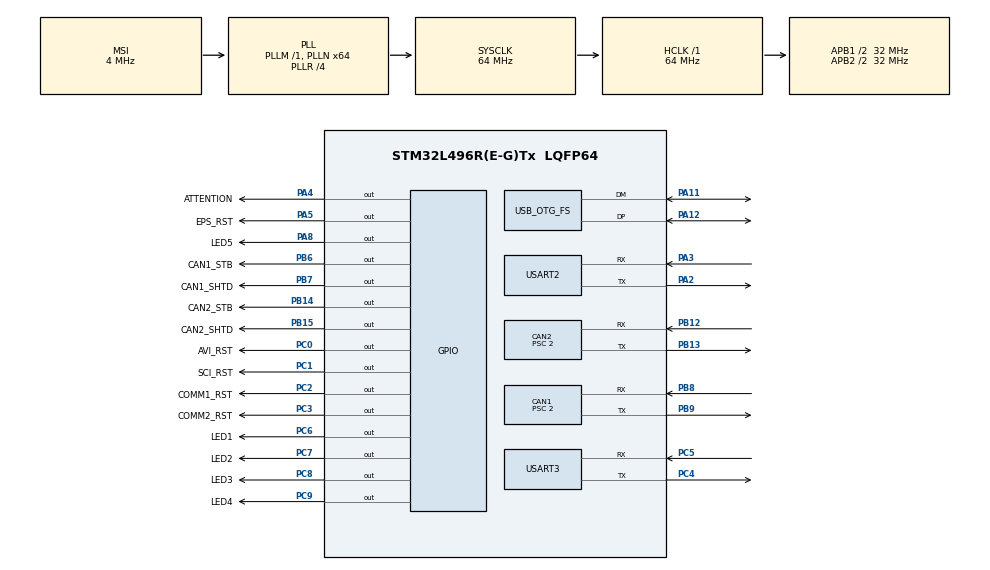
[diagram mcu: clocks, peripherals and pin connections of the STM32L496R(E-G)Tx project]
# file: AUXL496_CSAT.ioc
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CAN1.AWUM=ENABLE
CAN1.BS1=CAN_BS1_13TQ
CAN1.BS2=CAN_BS2_2TQ
CAN1.CalculateBaudRate=1000000
CAN1.CalculateTimeBit=1000
CAN1.CalculateTimeQuantum=62.5
CAN1.Prescaler=2
CAN1.TXFP=ENABLE
CAN2.AWUM=ENABLE
CAN2.BS1=CAN_BS1_13TQ
CAN2.BS2=CAN_BS2_2TQ
CAN2.CalculateBaudRate=1000000
CAN2.CalculateTimeBit=1000
CAN2.CalculateTimeQuantum=62.5
CAN2.Prescaler=2
CAN2.TXFP=ENABLE
Dma.Request0=USART2_RX
Dma.Request1=USART2_TX
Dma.Request2=USART3_RX
Dma.Request3=USART3_TX
Dma.USART2_RX.0.Direction=DMA_PERIPH_TO_MEMORY
Dma.USART2_RX.0.Instance=DMA1_Channel6
Dma.USART2_RX.0.MemDataAlignment=DMA_MDATAALIGN_BYTE
Dma.USART2_RX.0.MemInc=DMA_MINC_ENABLE
Dma.USART2_RX.0.Mode=DMA_NORMAL
Dma.USART2_RX.0.PeriphDataAlignment=DMA_PDATAALIGN_BYTE
Dma.USART2_RX.0.PeriphInc=DMA_PINC_DISABLE
Dma.USART2_RX.0.Priority=DMA_PRIORITY_LOW
Dma.USART2_TX.1.Direction=DMA_MEMORY_TO_PERIPH
Dma.USART2_TX.1.Instance=DMA1_Channel7
Dma.USART2_TX.1.MemDataAlignment=DMA_MDATAALIGN_BYTE
Dma.USART2_TX.1.MemInc=DMA_MINC_ENABLE
Dma.USART2_TX.1.Mode=DMA_NORMAL
Dma.USART2_TX.1.PeriphDataAlignment=DMA_PDATAALIGN_BYTE
Dma.USART2_TX.1.PeriphInc=DMA_PINC_DISABLE
Dma.USART2_TX.1.Priority=DMA_PRIORITY_LOW
Dma.USART3_RX.2.Direction=DMA_PERIPH_TO_MEMORY
Dma.USART3_RX.2.Instance=DMA1_Channel3
Dma.USART3_RX.2.MemDataAlignment=DMA_MDATAALIGN_BYTE
Dma.USART3_RX.2.MemInc=DMA_MINC_ENABLE
Dma.USART3_RX.2.Mode=DMA_NORMAL
Dma.USART3_RX.2.PeriphDataAlignment=DMA_PDATAALIGN_BYTE
Dma.USART3_RX.2.PeriphInc=DMA_PINC_DISABLE
Dma.USART3_RX.2.Priority=DMA_PRIORITY_LOW
Dma.USART3_TX.3.Direction=DMA_MEMORY_TO_PERIPH
Dma.USART3_TX.3.Instance=DMA1_Channel2
Dma.USART3_TX.3.MemDataAlignment=DMA_MDATAALIGN_BYTE
Dma.USART3_TX.3.MemInc=DMA_MINC_ENABLE
Dma.USART3_TX.3.Mode=DMA_NORMAL
Dma.USART3_TX.3.PeriphDataAlignment=DMA_PDATAALIGN_BYTE
Dma.USART3_TX.3.PeriphInc=DMA_PINC_DISABLE
Dma.USART3_TX.3.Priority=DMA_PRIORITY_LOW
Mcu.Family=STM32L4
Mcu.Name=STM32L496R(E-G)Tx
Mcu.Package=LQFP64
NVIC.CAN1_RX0_IRQn=true\:0\:0\:false\:false\:true\:true\:true\:true
NVIC.CAN1_RX1_IRQn=true\:0\:0\:false\:false\:true\:true\:true\:true
NVIC.CAN1_SCE_IRQn=true\:0\:0\:false\:false\:true\:true\:true\:true
NVIC.CAN2_RX0_IRQn=true\:0\:0\:false\:false\:true\:true\:true\:true
NVIC.CAN2_RX1_IRQn=true\:0\:0\:false\:false\:true\:true\:true\:true
NVIC.CAN2_SCE_IRQn=true\:0\:0\:false\:false\:true\:true\:true\:true
NVIC.DMA1_Channel2_IRQn=true\:0\:0\:false\:false\:true\:false\:true\:true
NVIC.DMA1_Channel3_IRQn=true\:0\:0\:false\:false\:true\:false\:true\:true
NVIC.DMA1_Channel6_IRQn=true\:0\:0\:false\:false\:true\:false\:true\:true
NVIC.DMA1_Channel7_IRQn=true\:0\:0\:false\:false\:true\:false\:true\:true
NVIC.OTG_FS_IRQn=true\:0\:0\:false\:false\:true\:false\:true\:true
NVIC.PriorityGroup=NVIC_PRIORITYGROUP_4
NVIC.USART2_IRQn=true\:0\:0\:false\:false\:true\:true\:true\:true
NVIC.USART3_IRQn=true\:0\:0\:false\:false\:true\:true\:true\:true
PA11.Mode=Device_Only
PA11.Signal=USB_OTG_FS_DM
PA12.Mode=Device_Only
PA12.Signal=USB_OTG_FS_DP
PA2.Mode=Asynchronous
PA2.Signal=USART2_TX
PA3.Mode=Asynchronous
PA3.Signal=USART2_RX
PA4.GPIO_Label=ATTENTION
PA4.PinState=GPIO_PIN_SET
PA4.Signal=GPIO_Output
PA5.GPIO_Label=EPS_RST
PA5.PinState=GPIO_PIN_SET
PA5.Signal=GPIO_Output
PA8.GPIO_Label=LED5
PA8.PinState=GPIO_PIN_RESET
PA8.Signal=GPIO_Output
PB12.Mode=CAN_Activate
PB12.Signal=CAN2_RX
PB13.Mode=CAN_Activate
PB13.Signal=CAN2_TX
PB14.GPIO_Label=CAN2_STB
PB14.Signal=GPIO_Output
PB15.GPIO_Label=CAN2_SHTD
PB15.Signal=GPIO_Output
PB6.GPIO_Label=CAN1_STB
PB6.Signal=GPIO_Output
PB7.GPIO_Label=CAN1_SHTD
PB7.Signal=GPIO_Output
PB8.Mode=CAN_Activate
PB8.Signal=CAN1_RX
PB9.Mode=CAN_Activate
PB9.Signal=CAN1_TX
PC0.GPIO_Label=AVI_RST
PC0.PinState=GPIO_PIN_SET
PC0.Signal=GPIO_Output
PC1.GPIO_Label=SCI_RST
PC1.PinState=GPIO_PIN_SET
PC1.Signal=GPIO_Output
PC2.GPIO_Label=COMM1_RST
PC2.PinState=GPIO_PIN_SET
PC2.Signal=GPIO_Output
PC3.GPIO_Label=COMM2_RST
PC3.PinState=GPIO_PIN_SET
PC3.Signal=GPIO_Output
PC4.Mode=Asynchronous
PC4.Signal=USART3_TX
PC5.Mode=Asynchronous
PC5.Signal=USART3_RX
PC6.GPIO_Label=LED1
PC6.Signal=GPIO_Output
PC7.GPIO_Label=LED2
PC7.Signal=GPIO_Output
PC8.GPIO_Label=LED3
PC8.Signal=GPIO_Output
PC9.GPIO_Label=LED4
PC9.Signal=GPIO_Output
ProjectManager.HeapSize=0x200
ProjectManager.StackSize=0x400
ProjectManager.TargetToolchain=STM32CubeIDE
RCC.ADCFreq_Value=48000000
RCC.AHBFreq_Value=64000000
RCC.APB1CLKDivider=RCC_HCLK_DIV2
RCC.APB1Freq_Value=32000000
RCC.APB1TimFreq_Value=64000000
RCC.APB2CLKDivider=RCC_HCLK_DIV2
RCC.APB2Freq_Value=32000000
RCC.APB2TimFreq_Value=64000000
RCC.CK48CLockSelection=RCC_USBCLKSOURCE_HSI48
RCC.CortexFreq_Value=64000000
RCC.FLatency=FLASH_LATENCY_3
RCC.HCLKFreq_Value=64000000
RCC.HSE_VALUE=8000000
RCC.HSI48_VALUE=48000000
RCC.HSI_VALUE=16000000
RCC.LSE_VALUE=32768
RCC.MSI_VALUE=4000000
RCC.PLLN=64
RCC.PLLR=RCC_PLLR_DIV4
RCC.PLLSAI1N=24
RCC.SYSCLKFreq_VALUE=64000000
RCC.SYSCLKSource=RCC_SYSCLKSOURCE_PLLCLK
RCC.USBFreq_Value=48000000
RCC.VCOOutputFreq_Value=256000000
USART2.SwapParam=ADVFEATURE_SWAP_ENABLE
USART2.VirtualMode-Asynchronous=VM_ASYNC
USART3.VirtualMode-Asynchronous=VM_ASYNC
USB_DEVICE.CLASS_NAME_FS=CDC
USB_DEVICE.VirtualMode=Cdc
USB_DEVICE.VirtualModeFS=Cdc_FS
USB_OTG_FS.VirtualMode=Device_Only
VP_RTC_VS_RTC_Activate.Mode=RTC_Enabled
VP_USB_DEVICE_VS_USB_DEVICE_CDC_FS.Mode=CDC_FS
board=custom

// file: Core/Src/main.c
/* USER CODE BEGIN Header */
/**
  ******************************************************************************
  * @file           : main.c
  * @brief          : Main program body
  ******************************************************************************
  * @attention
  *
  * Copyright (c) 2025 STMicroelectronics.
  * All rights reserved.
  *
  * This software is licensed under terms that can be found in the LICENSE file
  * in the root directory of this software component.
  * If no LICENSE file comes with this software, it is provided AS-IS.
  *
  ******************************************************************************
  */
/* USER CODE END Header */
#include "main.h"
#include "usb_device.h"

/* USER CODE BEGIN Includes */
#include "cppmain.h"
/* USER CODE END Includes */

CAN_HandleTypeDef hcan1;
CAN_HandleTypeDef hcan2;

RTC_HandleTypeDef hrtc;

UART_HandleTypeDef huart2;
UART_HandleTypeDef huart3;
DMA_HandleTypeDef hdma_usart2_rx;
DMA_HandleTypeDef hdma_usart2_tx;
DMA_HandleTypeDef hdma_usart3_rx;
DMA_HandleTypeDef hdma_usart3_tx;

void SystemClock_Config(void);
static void MX_GPIO_Init(void);
static void MX_DMA_Init(void);
static void MX_USART2_UART_Init(void);
static void MX_USART3_UART_Init(void);
static void MX_CAN1_Init(void);
static void MX_CAN2_Init(void);
static void MX_RTC_Init(void);

/* USER CODE BEGIN 0 */
extern int getentropy(void* buffer, size_t length) {
    (void)buffer;
    (void)length;
    return -1; // ENOSYS: Function not implemented
}
/* USER CODE END 0 */

int main(void)
{

  /* MCU Configuration--------------------------------------------------------*/

  /* Reset of all peripherals, Initializes the Flash interface and the Systick. */
  HAL_Init();

  /* Configure the system clock */
  SystemClock_Config();

  /* Initialize all configured peripherals */
  MX_GPIO_Init();
  MX_DMA_Init();
  MX_USART2_UART_Init();
  MX_USART3_UART_Init();
  MX_USB_DEVICE_Init();
  MX_CAN1_Init();
  MX_CAN2_Init();
  MX_RTC_Init();
  /* USER CODE BEGIN 2 */
  cppmain();

  /* USER CODE END 2 */

  /* Infinite loop */
  while (1)
  {

  }
}

void SystemClock_Config(void)
{
  RCC_OscInitTypeDef RCC_OscInitStruct = {0};
  RCC_ClkInitTypeDef RCC_ClkInitStruct = {0};

  /** Configure the main internal regulator output voltage
  */
  if (HAL_PWREx_ControlVoltageScaling(PWR_REGULATOR_VOLTAGE_SCALE1) != HAL_OK)
  {
    Error_Handler();
  }

  /** Initializes the RCC Oscillators according to the specified parameters
  * in the RCC_OscInitTypeDef structure.
  */
  RCC_OscInitStruct.OscillatorType = RCC_OSCILLATORTYPE_HSI48|RCC_OSCILLATORTYPE_LSI
                              |RCC_OSCILLATORTYPE_MSI;
  RCC_OscInitStruct.HSI48State = RCC_HSI48_ON;
  RCC_OscInitStruct.LSIState = RCC_LSI_ON;
  RCC_OscInitStruct.MSIState = RCC_MSI_ON;
  RCC_OscInitStruct.MSICalibrationValue = 0;
  RCC_OscInitStruct.MSIClockRange = RCC_MSIRANGE_6;
  RCC_OscInitStruct.PLL.PLLState = RCC_PLL_ON;
  RCC_OscInitStruct.PLL.PLLSource = RCC_PLLSOURCE_MSI;
  RCC_OscInitStruct.PLL.PLLM = 1;
  RCC_OscInitStruct.PLL.PLLN = 64;
  RCC_OscInitStruct.PLL.PLLP = RCC_PLLP_DIV2;
  RCC_OscInitStruct.PLL.PLLQ = RCC_PLLQ_DIV2;
  RCC_OscInitStruct.PLL.PLLR = RCC_PLLR_DIV4;
  if (HAL_RCC_OscConfig(&RCC_OscInitStruct) != HAL_OK)
  {
    Error_Handler();
  }

  /** Initializes the CPU, AHB and APB buses clocks
  */
  RCC_ClkInitStruct.ClockType = RCC_CLOCKTYPE_HCLK|RCC_CLOCKTYPE_SYSCLK
                              |RCC_CLOCKTYPE_PCLK1|RCC_CLOCKTYPE_PCLK2;
  RCC_ClkInitStruct.SYSCLKSource = RCC_SYSCLKSOURCE_PLLCLK;
  RCC_ClkInitStruct.AHBCLKDivider = RCC_SYSCLK_DIV1;
  RCC_ClkInitStruct.APB1CLKDivider = RCC_HCLK_DIV2;
  RCC_ClkInitStruct.APB2CLKDivider = RCC_HCLK_DIV2;

  if (HAL_RCC_ClockConfig(&RCC_ClkInitStruct, FLASH_LATENCY_3) != HAL_OK)
  {
    Error_Handler();
  }
}

static void MX_CAN1_Init(void)
{

  hcan1.Instance = CAN1;
  hcan1.Init.Prescaler = 2;
  hcan1.Init.Mode = CAN_MODE_NORMAL;
  hcan1.Init.SyncJumpWidth = CAN_SJW_1TQ;
  hcan1.Init.TimeSeg1 = CAN_BS1_13TQ;
  hcan1.Init.TimeSeg2 = CAN_BS2_2TQ;
  hcan1.Init.TimeTriggeredMode = DISABLE;
  hcan1.Init.AutoBusOff = DISABLE;
  hcan1.Init.AutoWakeUp = ENABLE;
  hcan1.Init.AutoRetransmission = DISABLE;
  hcan1.Init.ReceiveFifoLocked = DISABLE;
  hcan1.Init.TransmitFifoPriority = ENABLE;
  if (HAL_CAN_Init(&hcan1) != HAL_OK)
  {
    Error_Handler();
  }

}

static void MX_CAN2_Init(void)
{

  hcan2.Instance = CAN2;
  hcan2.Init.Prescaler = 2;
  hcan2.Init.Mode = CAN_MODE_NORMAL;
  hcan2.Init.SyncJumpWidth = CAN_SJW_1TQ;
  hcan2.Init.TimeSeg1 = CAN_BS1_13TQ;
  hcan2.Init.TimeSeg2 = CAN_BS2_2TQ;
  hcan2.Init.TimeTriggeredMode = DISABLE;
  hcan2.Init.AutoBusOff = DISABLE;
  hcan2.Init.AutoWakeUp = ENABLE;
  hcan2.Init.AutoRetransmission = DISABLE;
  hcan2.Init.ReceiveFifoLocked = DISABLE;
  hcan2.Init.TransmitFifoPriority = ENABLE;
  if (HAL_CAN_Init(&hcan2) != HAL_OK)
  {
    Error_Handler();
  }

}

static void MX_RTC_Init(void)
{

  /** Initialize RTC Only
  */
  hrtc.Instance = RTC;
  hrtc.Init.HourFormat = RTC_HOURFORMAT_24;
  hrtc.Init.AsynchPrediv = 127;
  hrtc.Init.SynchPrediv = 255;
  hrtc.Init.OutPut = RTC_OUTPUT_DISABLE;
  hrtc.Init.OutPutRemap = RTC_OUTPUT_REMAP_NONE;
  hrtc.Init.OutPutPolarity = RTC_OUTPUT_POLARITY_HIGH;
  hrtc.Init.OutPutType = RTC_OUTPUT_TYPE_OPENDRAIN;
  if (HAL_RTC_Init(&hrtc) != HAL_OK)
  {
    Error_Handler();
  }

}

static void MX_USART2_UART_Init(void)
{

  huart2.Instance = USART2;
  huart2.Init.BaudRate = 115200;
  huart2.Init.WordLength = UART_WORDLENGTH_8B;
  huart2.Init.StopBits = UART_STOPBITS_1;
  huart2.Init.Parity = UART_PARITY_NONE;
  huart2.Init.Mode = UART_MODE_TX_RX;
  huart2.Init.HwFlowCtl = UART_HWCONTROL_NONE;
  huart2.Init.OverSampling = UART_OVERSAMPLING_16;
  huart2.Init.OneBitSampling = UART_ONE_BIT_SAMPLE_DISABLE;
  huart2.AdvancedInit.AdvFeatureInit = UART_ADVFEATURE_SWAP_INIT;
  huart2.AdvancedInit.Swap = UART_ADVFEATURE_SWAP_ENABLE;
  if (HAL_UART_Init(&huart2) != HAL_OK)
  {
    Error_Handler();
  }

}

static void MX_USART3_UART_Init(void)
{

  huart3.Instance = USART3;
  huart3.Init.BaudRate = 115200;
  huart3.Init.WordLength = UART_WORDLENGTH_8B;
  huart3.Init.StopBits = UART_STOPBITS_1;
  huart3.Init.Parity = UART_PARITY_NONE;
  huart3.Init.Mode = UART_MODE_TX_RX;
  huart3.Init.HwFlowCtl = UART_HWCONTROL_NONE;
  huart3.Init.OverSampling = UART_OVERSAMPLING_16;
  huart3.Init.OneBitSampling = UART_ONE_BIT_SAMPLE_DISABLE;
  huart3.AdvancedInit.AdvFeatureInit = UART_ADVFEATURE_NO_INIT;
  if (HAL_UART_Init(&huart3) != HAL_OK)
  {
    Error_Handler();
  }

}

static void MX_DMA_Init(void)
{

  /* DMA controller clock enable */
  __HAL_RCC_DMA1_CLK_ENABLE();

  /* DMA interrupt init */
  /* DMA1_Channel2_IRQn interrupt configuration */
  HAL_NVIC_SetPriority(DMA1_Channel2_IRQn, 0, 0);
  HAL_NVIC_EnableIRQ(DMA1_Channel2_IRQn);
  /* DMA1_Channel3_IRQn interrupt configuration */
  HAL_NVIC_SetPriority(DMA1_Channel3_IRQn, 0, 0);
  HAL_NVIC_EnableIRQ(DMA1_Channel3_IRQn);
  /* DMA1_Channel6_IRQn interrupt configuration */
  HAL_NVIC_SetPriority(DMA1_Channel6_IRQn, 0, 0);
  HAL_NVIC_EnableIRQ(DMA1_Channel6_IRQn);
  /* DMA1_Channel7_IRQn interrupt configuration */
  HAL_NVIC_SetPriority(DMA1_Channel7_IRQn, 0, 0);
  HAL_NVIC_EnableIRQ(DMA1_Channel7_IRQn);

}

static void MX_GPIO_Init(void)
{
  GPIO_InitTypeDef GPIO_InitStruct = {0};

  /* GPIO Ports Clock Enable */
  __HAL_RCC_GPIOC_CLK_ENABLE();
  __HAL_RCC_GPIOA_CLK_ENABLE();
  __HAL_RCC_GPIOB_CLK_ENABLE();

  /*Configure GPIO pin Output Level */
  HAL_GPIO_WritePin(GPIOC, AVI_RST_Pin|SCI_RST_Pin|COMM1_RST_Pin|COMM2_RST_Pin, GPIO_PIN_SET);

  /*Configure GPIO pin Output Level */
  HAL_GPIO_WritePin(GPIOA, ATTENTION_Pin|EPS_RST_Pin, GPIO_PIN_SET);

  /*Configure GPIO pin Output Level */
  HAL_GPIO_WritePin(GPIOB, CAN2_STB_Pin|CAN2_SHTD_Pin|CAN1_STB_Pin|CAN1_SHTD_Pin, GPIO_PIN_RESET);

  /*Configure GPIO pin Output Level */
  HAL_GPIO_WritePin(GPIOC, LED1_Pin|LED2_Pin|LED3_Pin|LED4_Pin, GPIO_PIN_RESET);

  /*Configure GPIO pin Output Level */
  HAL_GPIO_WritePin(LED5_GPIO_Port, LED5_Pin, GPIO_PIN_RESET);

  /*Configure GPIO pins : AVI_RST_Pin SCI_RST_Pin COMM1_RST_Pin COMM2_RST_Pin
                           LED1_Pin LED2_Pin LED3_Pin LED4_Pin */
  GPIO_InitStruct.Pin = AVI_RST_Pin|SCI_RST_Pin|COMM1_RST_Pin|COMM2_RST_Pin
                          |LED1_Pin|LED2_Pin|LED3_Pin|LED4_Pin;
  GPIO_InitStruct.Mode = GPIO_MODE_OUTPUT_PP;
  GPIO_InitStruct.Pull = GPIO_NOPULL;
  GPIO_InitStruct.Speed = GPIO_SPEED_FREQ_LOW;
  HAL_GPIO_Init(GPIOC, &GPIO_InitStruct);

  /*Configure GPIO pins : ATTENTION_Pin EPS_RST_Pin LED5_Pin */
  GPIO_InitStruct.Pin = ATTENTION_Pin|EPS_RST_Pin|LED5_Pin;
  GPIO_InitStruct.Mode = GPIO_MODE_OUTPUT_PP;
  GPIO_InitStruct.Pull = GPIO_NOPULL;
  GPIO_InitStruct.Speed = GPIO_SPEED_FREQ_LOW;
  HAL_GPIO_Init(GPIOA, &GPIO_InitStruct);

  /*Configure GPIO pins : CAN2_STB_Pin CAN2_SHTD_Pin CAN1_STB_Pin CAN1_SHTD_Pin */
  GPIO_InitStruct.Pin = CAN2_STB_Pin|CAN2_SHTD_Pin|CAN1_STB_Pin|CAN1_SHTD_Pin;
  GPIO_InitStruct.Mode = GPIO_MODE_OUTPUT_PP;
  GPIO_InitStruct.Pull = GPIO_NOPULL;
  GPIO_InitStruct.Speed = GPIO_SPEED_FREQ_LOW;
  HAL_GPIO_Init(GPIOB, &GPIO_InitStruct);

}

void Error_Handler(void)
{
  __disable_irq();
  while (1)
  {
  }
}
